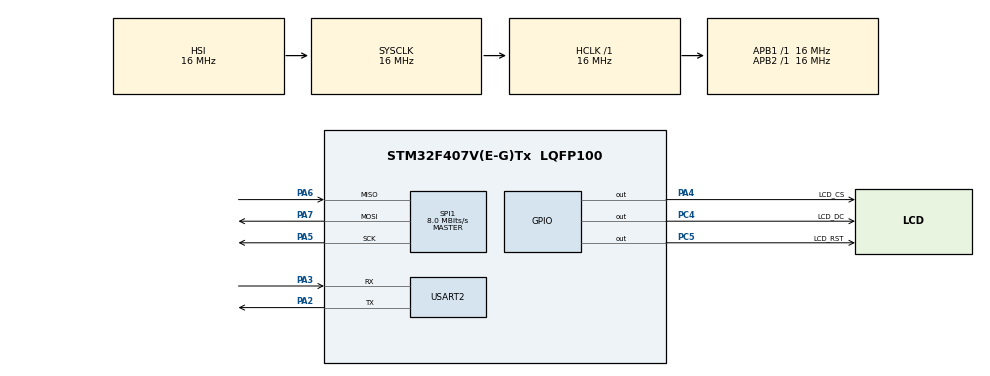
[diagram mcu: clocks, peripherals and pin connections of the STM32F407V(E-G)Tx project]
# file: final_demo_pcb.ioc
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Mcu.Family=STM32F4
PA6.Mode=Full_Duplex_Master
PH0-OSC_IN.Signal=RCC_OSC_IN
RCC.CortexFreq_Value=16000000
PA7.Mode=Full_Duplex_Master
SPI1.VirtualType=VM_MASTER
PC4.Signal=GPIO_Output
NVIC.USART2_IRQn=true\:0\:0\:false\:false\:true\:true\:true
ProjectManager.StackSize=0x400
PA3.Mode=Asynchronous
ProjectManager.TargetToolchain=STM32CubeIDE
SPI1.Direction=SPI_DIRECTION_2LINES
SPI1.CalculateBaudRate=8.0 MBits/s
RCC.LSE_VALUE=32768
RCC.AHBFreq_Value=16000000
PH0-OSC_IN.Mode=HSE-External-Oscillator
PA5.Signal=SPI1_SCK
RCC.HSE_VALUE=25000000
board=custom
RCC.VCOOutputFreq_Value=192000000
RCC.APB2Freq_Value=16000000
PC4.GPIO_Label=LCD_DC
SPI1.Mode=SPI_MODE_MASTER
PH1-OSC_OUT.Signal=RCC_OSC_OUT
Mcu.Name=STM32F407V(E-G)Tx
PA2.Signal=USART2_TX
PH1-OSC_OUT.Mode=HSE-External-Oscillator
PA4.Signal=GPIO_Output
RCC.SYSCLKFreq_VALUE=16000000
Mcu.Package=LQFP100
PA6.Signal=SPI1_MISO
PC5.GPIO_Label=LCD_RST
USART2.VirtualMode=VM_ASYNC
ProjectManager.HeapSize=0x200
RCC.HSI_VALUE=16000000
NVIC.PriorityGroup=NVIC_PRIORITYGROUP_4
PA2.Mode=Asynchronous
PC5.Signal=GPIO_Output
RCC.APB1Freq_Value=16000000
PA4.GPIO_Label=LCD_CS
PA3.Signal=USART2_RX
PA5.Mode=Full_Duplex_Master
PA7.Signal=SPI1_MOSI

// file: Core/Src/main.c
/* USER CODE BEGIN Header */
/**
  ******************************************************************************
  * @file           : main.c
  * @brief          : Main program body
  ******************************************************************************
  * @attention
  *
  * <h2><center>&copy; Copyright (c) 2021 STMicroelectronics.
  * All rights reserved.</center></h2>
  *
  * This software component is licensed by ST under BSD 3-Clause license,
  * the "License"; You may not use this file except in compliance with the
  * License. You may obtain a copy of the License at:
  *                        opensource.org/licenses/BSD-3-Clause
  *
  ******************************************************************************
  */
/* USER CODE END Header */
#include "main.h"

SPI_HandleTypeDef hspi1;

UART_HandleTypeDef huart2;

void SystemClock_Config(void);
static void MX_GPIO_Init(void);
static void MX_SPI1_Init(void);
static void MX_USART2_UART_Init(void);

/* USER CODE BEGIN 0 */
char Total[100];
char string[100];
char string2[100];
/* USER CODE END 0 */

int main(void)
{

  /* MCU Configuration--------------------------------------------------------*/

  /* Reset of all peripherals, Initializes the Flash interface and the Systick. */
  HAL_Init();

  /* Configure the system clock */
  SystemClock_Config();

  /* Initialize all configured peripherals */
  MX_GPIO_Init();
  MX_SPI1_Init();
  MX_USART2_UART_Init();
  /* USER CODE BEGIN 2 */
  ILI9341_Init(&hspi1, LCD_CS_GPIO_Port, LCD_CS_Pin, LCD_DC_GPIO_Port, LCD_DC_Pin,
  		  LCD_RST_GPIO_Port, LCD_RST_Pin);
    ILI9341_setRotation(2);
    ILI9341_printText("Connecting....", 20, 30, COLOR_WHITE, COLOR_WHITE, 1);
    ESP_Init("neyse", "12345678");
    ILI9341_Fill(COLOR_BLACK);
    ILI9341_printText("WELCOME!", 20, 30, COLOR_WHITE, COLOR_BLACK, 3);
    ILI9341_printText("LOADING WEATHER", 20, 90, COLOR_WHITE, COLOR_BLACK, 3);
    ILI9341_printText(",TIME AND DATE", 20, 120, COLOR_WHITE, COLOR_BLACK, 3);

  /* USER CODE END 2 */

  /* Infinite loop */
  while (1)
  {
	  ESP_GetData_1("64POEVJJ473SUR0V", Total);
	  	  HAL_Delay(20000);
	  	  ILI9341_Fill(COLOR_NAVY);
	  	  ILI9341_printText("Weather:", 0, 30, COLOR_WHITE, COLOR_NAVY, 3);
	  	  ILI9341_printText(Total, 0, 60, COLOR_WHITE, COLOR_NAVY, 2);
	  	  ILI9341_printText("Date:", 0, 90, COLOR_WHITE, COLOR_NAVY, 3);
	  	  ESP_GetData_2("RPGNBG4MTVD5HSAA", string);
	  	  ILI9341_printText(string, -10, 120, COLOR_WHITE, COLOR_NAVY, 2);
	  	  ILI9341_printText("Time:",0, 150, COLOR_WHITE, COLOR_NAVY, 3);
	  	  ESP_GetData_3("BGFP08OIRF21Y2YG", string2);
	  	  ILI9341_printText(string2, 0, 180, COLOR_WHITE, COLOR_NAVY, 2);
  }
}

void SystemClock_Config(void)
{
  RCC_OscInitTypeDef RCC_OscInitStruct = {0};
  RCC_ClkInitTypeDef RCC_ClkInitStruct = {0};

  /** Configure the main internal regulator output voltage
  */
  __HAL_RCC_PWR_CLK_ENABLE();
  __HAL_PWR_VOLTAGESCALING_CONFIG(PWR_REGULATOR_VOLTAGE_SCALE1);
  /** Initializes the RCC Oscillators according to the specified parameters
  * in the RCC_OscInitTypeDef structure.
  */
  RCC_OscInitStruct.OscillatorType = RCC_OSCILLATORTYPE_HSI;
  RCC_OscInitStruct.HSIState = RCC_HSI_ON;
  RCC_OscInitStruct.HSICalibrationValue = RCC_HSICALIBRATION_DEFAULT;
  RCC_OscInitStruct.PLL.PLLState = RCC_PLL_NONE;
  if (HAL_RCC_OscConfig(&RCC_OscInitStruct) != HAL_OK)
  {
    Error_Handler();
  }
  /** Initializes the CPU, AHB and APB buses clocks
  */
  RCC_ClkInitStruct.ClockType = RCC_CLOCKTYPE_HCLK|RCC_CLOCKTYPE_SYSCLK
                              |RCC_CLOCKTYPE_PCLK1|RCC_CLOCKTYPE_PCLK2;
  RCC_ClkInitStruct.SYSCLKSource = RCC_SYSCLKSOURCE_HSI;
  RCC_ClkInitStruct.AHBCLKDivider = RCC_SYSCLK_DIV1;
  RCC_ClkInitStruct.APB1CLKDivider = RCC_HCLK_DIV1;
  RCC_ClkInitStruct.APB2CLKDivider = RCC_HCLK_DIV1;

  if (HAL_RCC_ClockConfig(&RCC_ClkInitStruct, FLASH_LATENCY_0) != HAL_OK)
  {
    Error_Handler();
  }
}

static void MX_SPI1_Init(void)
{

  /* SPI1 parameter configuration*/
  hspi1.Instance = SPI1;
  hspi1.Init.Mode = SPI_MODE_MASTER;
  hspi1.Init.Direction = SPI_DIRECTION_2LINES;
  hspi1.Init.DataSize = SPI_DATASIZE_8BIT;
  hspi1.Init.CLKPolarity = SPI_POLARITY_LOW;
  hspi1.Init.CLKPhase = SPI_PHASE_1EDGE;
  hspi1.Init.NSS = SPI_NSS_SOFT;
  hspi1.Init.BaudRatePrescaler = SPI_BAUDRATEPRESCALER_2;
  hspi1.Init.FirstBit = SPI_FIRSTBIT_MSB;
  hspi1.Init.TIMode = SPI_TIMODE_DISABLE;
  hspi1.Init.CRCCalculation = SPI_CRCCALCULATION_DISABLE;
  hspi1.Init.CRCPolynomial = 10;
  if (HAL_SPI_Init(&hspi1) != HAL_OK)
  {
    Error_Handler();
  }

}

static void MX_USART2_UART_Init(void)
{

  huart2.Instance = USART2;
  huart2.Init.BaudRate = 115200;
  huart2.Init.WordLength = UART_WORDLENGTH_8B;
  huart2.Init.StopBits = UART_STOPBITS_1;
  huart2.Init.Parity = UART_PARITY_NONE;
  huart2.Init.Mode = UART_MODE_TX_RX;
  huart2.Init.HwFlowCtl = UART_HWCONTROL_NONE;
  huart2.Init.OverSampling = UART_OVERSAMPLING_16;
  if (HAL_UART_Init(&huart2) != HAL_OK)
  {
    Error_Handler();
  }

}

static void MX_GPIO_Init(void)
{
  GPIO_InitTypeDef GPIO_InitStruct = {0};

  /* GPIO Ports Clock Enable */
  __HAL_RCC_GPIOH_CLK_ENABLE();
  __HAL_RCC_GPIOA_CLK_ENABLE();
  __HAL_RCC_GPIOC_CLK_ENABLE();

  /*Configure GPIO pin Output Level */
  HAL_GPIO_WritePin(LCD_CS_GPIO_Port, LCD_CS_Pin, GPIO_PIN_RESET);

  /*Configure GPIO pin Output Level */
  HAL_GPIO_WritePin(GPIOC, LCD_DC_Pin|LCD_RST_Pin, GPIO_PIN_RESET);

  /*Configure GPIO pin : LCD_CS_Pin */
  GPIO_InitStruct.Pin = LCD_CS_Pin;
  GPIO_InitStruct.Mode = GPIO_MODE_OUTPUT_PP;
  GPIO_InitStruct.Pull = GPIO_NOPULL;
  GPIO_InitStruct.Speed = GPIO_SPEED_FREQ_LOW;
  HAL_GPIO_Init(LCD_CS_GPIO_Port, &GPIO_InitStruct);

  /*Configure GPIO pins : LCD_DC_Pin LCD_RST_Pin */
  GPIO_InitStruct.Pin = LCD_DC_Pin|LCD_RST_Pin;
  GPIO_InitStruct.Mode = GPIO_MODE_OUTPUT_PP;
  GPIO_InitStruct.Pull = GPIO_NOPULL;
  GPIO_InitStruct.Speed = GPIO_SPEED_FREQ_LOW;
  HAL_GPIO_Init(GPIOC, &GPIO_InitStruct);

}

void Error_Handler(void)
{
  __disable_irq();
  while (1)
  {
  }
}

/************************ (C) COPYRIGHT STMicroelectronics *****END OF FILE****/
